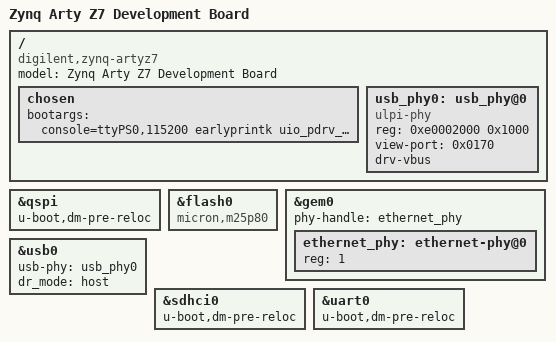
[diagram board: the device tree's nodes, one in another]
/include/ "system-conf.dtsi"
#include <dt-bindings/gpio/gpio.h>
/ {
	model = "Zynq Arty Z7 Development Board";
	compatible = "digilent,zynq-artyz7", "xlnx,zynq-7000";

	chosen {
		bootargs = "console=ttyPS0,115200 earlyprintk uio_pdrv_genirq.of_id=generic-uio";
	};

	usb_phy0: usb_phy@0 {
		compatible = "ulpi-phy";
		#phy-cells = <0>;
		reg = <0xe0002000 0x1000>;
		view-port = <0x0170>;
		drv-vbus;
	};

};

&qspi {
	u-boot,dm-pre-reloc;
};

&flash0 {
	compatible = "micron,m25p80", "s25fl128s", "spi-flash";
};

&gem0 {
	phy-handle = <&ethernet_phy>;

	ethernet_phy: ethernet-phy@0 { /* rtl8211e-vl */
	reg = <1>;
	device_type = "ethernet-phy";
	};
};

&usb0 {	
	usb-phy = <&usb_phy0>;
	dr_mode = "host";
	/delete-property/ usb-reset;
};

&sdhci0 {
	u-boot,dm-pre-reloc;
};

&uart0 {
	u-boot,dm-pre-reloc;
};


